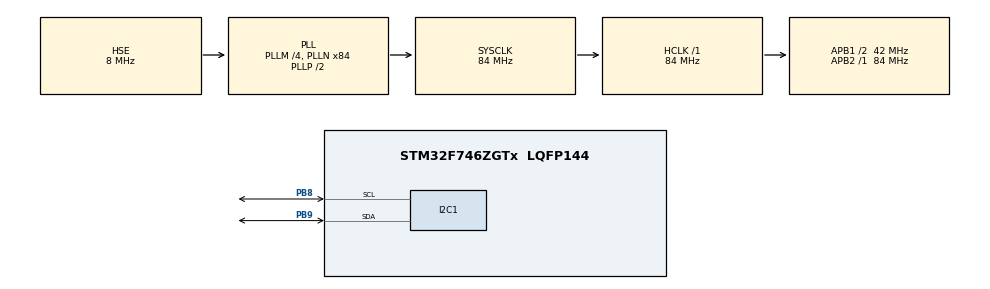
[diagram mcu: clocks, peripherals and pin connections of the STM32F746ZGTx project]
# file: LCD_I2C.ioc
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I2C1.Timing=0x00A0A3F7
Mcu.Family=STM32F7
Mcu.Name=STM32F746ZGTx
Mcu.Package=LQFP144
NVIC.PriorityGroup=NVIC_PRIORITYGROUP_4
PB8.Mode=I2C
PB8.Signal=I2C1_SCL
PB9.Mode=I2C
PB9.Signal=I2C1_SDA
PH0/OSC_IN.Mode=HSE-External-Oscillator
PH0/OSC_IN.Signal=RCC_OSC_IN
PH1/OSC_OUT.Mode=HSE-External-Oscillator
PH1/OSC_OUT.Signal=RCC_OSC_OUT
ProjectManager.HeapSize=0x200
ProjectManager.StackSize=0x400
ProjectManager.TargetToolchain=MDK-ARM V5
RCC.48MHZClocksFreq_Value=24000000
RCC.AHBFreq_Value=84000000
RCC.APB1CLKDivider=RCC_HCLK_DIV2
RCC.APB1Freq_Value=42000000
RCC.APB1TimFreq_Value=84000000
RCC.APB2Freq_Value=84000000
RCC.APB2TimFreq_Value=84000000
RCC.CortexFreq_Value=84000000
RCC.HCLKFreq_Value=84000000
RCC.HSE_VALUE=8000000
RCC.HSI_VALUE=16000000
RCC.PLLM=4
RCC.PLLMUL=RCC_PLL_MUL9
RCC.PLLN=84
RCC.PLLQ=3
RCC.PLLSourceVirtual=RCC_PLLSOURCE_HSE
RCC.PRESCALERUSB=RCC_USBCLKSOURCE_PLL_DIV1_5
RCC.SYSCLKFreq_VALUE=84000000
RCC.SYSCLKSource=RCC_SYSCLKSOURCE_PLLCLK
RCC.SYSCLKSourceVirtual=RCC_SYSCLKSOURCE_PLLCLK
RCC.USBFreq_Value=56000000
RCC.VCOOutputFreq_Value=168000000
board=NUCLEO-F746ZG

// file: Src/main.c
/**
  ******************************************************************************
  * @file           : main.c
  * @brief          : Main program body
  ******************************************************************************
  ** This notice applies to any and all portions of this file
  * that are not between comment pairs USER CODE BEGIN and
  * USER CODE END. Other portions of this file, whether
  * inserted by the user or by software development tools
  * are owned by their respective copyright owners.
  *
  * COPYRIGHT(c) 2018 STMicroelectronics
  *
  * Redistribution and use in source and binary forms, with or without modification,
  * are permitted provided that the following conditions are met:
  *   1. Redistributions of source code must retain the above copyright notice,
  *      this list of conditions and the following disclaimer.
  *   2. Redistributions in binary form must reproduce the above copyright notice,
  *      this list of conditions and the following disclaimer in the documentation
  *      and/or other materials provided with the distribution.
  *   3. Neither the name of STMicroelectronics nor the names of its contributors
  *      may be used to endorse or promote products derived from this software
  *      without specific prior written permission.
  *
  * THIS SOFTWARE IS PROVIDED BY THE COPYRIGHT HOLDERS AND CONTRIBUTORS "AS IS"
  * AND ANY EXPRESS OR IMPLIED WARRANTIES, INCLUDING, BUT NOT LIMITED TO, THE
  * IMPLIED WARRANTIES OF MERCHANTABILITY AND FITNESS FOR A PARTICULAR PURPOSE ARE
  * DISCLAIMED. IN NO EVENT SHALL THE COPYRIGHT HOLDER OR CONTRIBUTORS BE LIABLE
  * FOR ANY DIRECT, INDIRECT, INCIDENTAL, SPECIAL, EXEMPLARY, OR CONSEQUENTIAL
  * DAMAGES (INCLUDING, BUT NOT LIMITED TO, PROCUREMENT OF SUBSTITUTE GOODS OR
  * SERVICES; LOSS OF USE, DATA, OR PROFITS; OR BUSINESS INTERRUPTION) HOWEVER
  * CAUSED AND ON ANY THEORY OF LIABILITY, WHETHER IN CONTRACT, STRICT LIABILITY,
  * OR TORT (INCLUDING NEGLIGENCE OR OTHERWISE) ARISING IN ANY WAY OUT OF THE USE
  * OF THIS SOFTWARE, EVEN IF ADVISED OF THE POSSIBILITY OF SUCH DAMAGE.
  *
  ******************************************************************************
  */
#include "main.h"
#include "stm32f7xx_hal.h"

I2C_HandleTypeDef hi2c1;

/* USER CODE BEGIN PV */
/* Private variables ---------------------------------------------------------*/

/* USER CODE END PV */

void SystemClock_Config(void);
static void MX_GPIO_Init(void);
static void MX_I2C1_Init(void);

/* USER CODE BEGIN PFP */
/* Private function prototypes -----------------------------------------------*/

/* USER CODE END PFP */

 void lcd_send_cmd (char cmd)
   {
        char data_u, data_l;
	uint8_t data_t[4];
	data_u = cmd&0xf0;    // select only upper nibble
	data_l = (cmd<<4)&0xf0;    // select only lower nibble
	data_t[0] = data_u|0x04;  //en=1, rs=0
	data_t[1] = data_u;  //en=0, rs=0
	data_t[2] = data_l|0x04;  //en=1, rs=0
	data_t[3] = data_l;  //en=0, rs=0
	HAL_I2C_Master_Transmit (&hi2c1, 0x4E, (uint8_t *) data_t, 4, 100);
   }

void lcd_send_data (char data)
{
	char data_u, data_l;
	uint8_t data_t[4];
	data_u = data&0xf0;    // upper data nibble
	data_l = (data<<4)&0xf0;    // lower data nibble
	data_t[0] = data_u|0x05;  //en=1, rs=0
	data_t[1] = data_u|0x01;  //en=0, rs=0
	data_t[2] = data_l|0x05;  //en=1, rs=0
	data_t[3] = data_l|0x01;  //en=0, rs=0
	HAL_I2C_Master_Transmit (&hi2c1, 0x4E,(uint8_t *) data_t, 4, 100);
}

void lcd_init(void)
{
lcd_send_cmd(0x02);

lcd_send_cmd(0x28);

lcd_send_cmd(0x0c);

lcd_send_cmd(0x80);
}

void lce_send_string(char *str)
{
while(*str)lcd_send_data(*str++);
}

char num[] = {'1','2','3','4','5','6','7','8','9'};
int main(void)
{

  /* MCU Configuration----------------------------------------------------------*/

  /* Reset of all peripherals, Initializes the Flash interface and the Systick. */
  HAL_Init();

  /* Configure the system clock */
  SystemClock_Config();

  /* Initialize all configured peripherals */
  MX_GPIO_Init();
  MX_I2C1_Init();
  /* USER CODE BEGIN 2 */
  lcd_init(); // initialise lcd
  lcd_send_cmd(0x01);
  lcd_send_cmd(0x80);// bring cursor to 1st row 1st col

lce_send_string("HELLO WORLD!");
  /* USER CODE END 2 */

  /* Infinite loop */
  /* USER CODE BEGIN WHILE */
  while (1)
  {
	/* for(int i = 0; i <9;i++){
	 lcd_send_data(num[i]);
		 HAL_Delay(1000);
		 lcd_send_cmd(0x80);
	 }
		*/

  /* USER CODE END WHILE */

  }

}

void SystemClock_Config(void)
{

  RCC_OscInitTypeDef RCC_OscInitStruct;
  RCC_ClkInitTypeDef RCC_ClkInitStruct;
  RCC_PeriphCLKInitTypeDef PeriphClkInitStruct;

    /**Configure the main internal regulator output voltage
    */
  __HAL_RCC_PWR_CLK_ENABLE();

  __HAL_PWR_VOLTAGESCALING_CONFIG(PWR_REGULATOR_VOLTAGE_SCALE3);

    /**Initializes the CPU, AHB and APB busses clocks
    */
  RCC_OscInitStruct.OscillatorType = RCC_OSCILLATORTYPE_HSE;
  RCC_OscInitStruct.HSEState = RCC_HSE_ON;
  RCC_OscInitStruct.PLL.PLLState = RCC_PLL_ON;
  RCC_OscInitStruct.PLL.PLLSource = RCC_PLLSOURCE_HSE;
  RCC_OscInitStruct.PLL.PLLM = 4;
  RCC_OscInitStruct.PLL.PLLN = 84;
  RCC_OscInitStruct.PLL.PLLP = RCC_PLLP_DIV2;
  RCC_OscInitStruct.PLL.PLLQ = 3;
  if (HAL_RCC_OscConfig(&RCC_OscInitStruct) != HAL_OK)
  {
    _Error_Handler(__FILE__, __LINE__);
  }

    /**Initializes the CPU, AHB and APB busses clocks
    */
  RCC_ClkInitStruct.ClockType = RCC_CLOCKTYPE_HCLK|RCC_CLOCKTYPE_SYSCLK
                              |RCC_CLOCKTYPE_PCLK1|RCC_CLOCKTYPE_PCLK2;
  RCC_ClkInitStruct.SYSCLKSource = RCC_SYSCLKSOURCE_PLLCLK;
  RCC_ClkInitStruct.AHBCLKDivider = RCC_SYSCLK_DIV1;
  RCC_ClkInitStruct.APB1CLKDivider = RCC_HCLK_DIV2;
  RCC_ClkInitStruct.APB2CLKDivider = RCC_HCLK_DIV1;

  if (HAL_RCC_ClockConfig(&RCC_ClkInitStruct, FLASH_LATENCY_2) != HAL_OK)
  {
    _Error_Handler(__FILE__, __LINE__);
  }

  PeriphClkInitStruct.PeriphClockSelection = RCC_PERIPHCLK_I2C1;
  PeriphClkInitStruct.I2c1ClockSelection = RCC_I2C1CLKSOURCE_PCLK1;
  if (HAL_RCCEx_PeriphCLKConfig(&PeriphClkInitStruct) != HAL_OK)
  {
    _Error_Handler(__FILE__, __LINE__);
  }

    /**Configure the Systick interrupt time
    */
  HAL_SYSTICK_Config(HAL_RCC_GetHCLKFreq()/1000);

    /**Configure the Systick
    */
  HAL_SYSTICK_CLKSourceConfig(SYSTICK_CLKSOURCE_HCLK);

  /* SysTick_IRQn interrupt configuration */
  HAL_NVIC_SetPriority(SysTick_IRQn, 0, 0);
}

/* I2C1 init function */
static void MX_I2C1_Init(void)
{

  hi2c1.Instance = I2C1;
  hi2c1.Init.Timing = 0x00A0A3F7;
  hi2c1.Init.OwnAddress1 = 0;
  hi2c1.Init.AddressingMode = I2C_ADDRESSINGMODE_7BIT;
  hi2c1.Init.DualAddressMode = I2C_DUALADDRESS_DISABLE;
  hi2c1.Init.OwnAddress2 = 0;
  hi2c1.Init.OwnAddress2Masks = I2C_OA2_NOMASK;
  hi2c1.Init.GeneralCallMode = I2C_GENERALCALL_DISABLE;
  hi2c1.Init.NoStretchMode = I2C_NOSTRETCH_DISABLE;
  if (HAL_I2C_Init(&hi2c1) != HAL_OK)
  {
    _Error_Handler(__FILE__, __LINE__);
  }

    /**Configure Analogue filter
    */
  if (HAL_I2CEx_ConfigAnalogFilter(&hi2c1, I2C_ANALOGFILTER_ENABLE) != HAL_OK)
  {
    _Error_Handler(__FILE__, __LINE__);
  }

    /**Configure Digital filter
    */
  if (HAL_I2CEx_ConfigDigitalFilter(&hi2c1, 0) != HAL_OK)
  {
    _Error_Handler(__FILE__, __LINE__);
  }

}

/** Configure pins as
        * Analog
        * Input
        * Output
        * EVENT_OUT
        * EXTI
*/
static void MX_GPIO_Init(void)
{

  /* GPIO Ports Clock Enable */
  __HAL_RCC_GPIOH_CLK_ENABLE();
  __HAL_RCC_GPIOB_CLK_ENABLE();

}

void _Error_Handler(char *file, int line)
{
  while(1)
  {
  }
}

/************************ (C) COPYRIGHT STMicroelectronics *****END OF FILE****/
